VERSION ""

NS_ :

BS_:

BU_: EBCM ADAS PCM EPS VSA SCM BDY XXX EPB EON

BO_ 145 KINEMATICS: 8 XXX
 SG_ LAT_ACCEL : 7|8@0+ (0.02,-2.56) [-20|20] "m/s2" EON
 SG_ YAW : 39|8@0- (0.02,0) [0|255] "" XXX

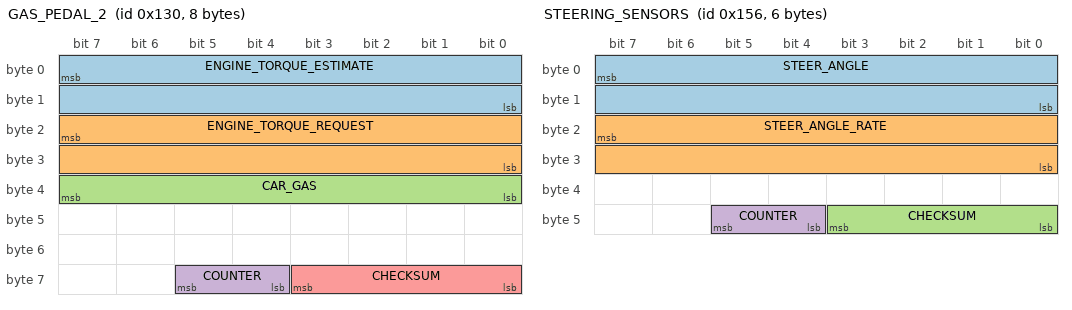
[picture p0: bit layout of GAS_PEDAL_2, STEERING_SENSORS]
BO_ 304 GAS_PEDAL_2: 8 PCM
 SG_ ENGINE_TORQUE_ESTIMATE : 7|16@0- (1,0) [-1000|1000] "Nm" EON
 SG_ ENGINE_TORQUE_REQUEST : 23|16@0- (1,0) [-1000|1000] "Nm" EON
 SG_ CAR_GAS : 39|8@0+ (1,0) [0|255] "" EON
 SG_ COUNTER : 61|2@0+ (1,0) [0|3] "" EON
 SG_ CHECKSUM : 59|4@0+ (1,0) [0|15] "" EON

BO_ 342 STEERING_SENSORS: 6 EPS
 SG_ STEER_ANGLE : 7|16@0- (-0.1,0) [-500|500] "deg" EON
 SG_ STEER_ANGLE_RATE : 23|16@0- (1,0) [-3000|3000] "deg/s" EON
 SG_ CHECKSUM : 43|4@0+ (1,0) [0|3] "" EON
 SG_ COUNTER : 45|2@0+ (1,0) [0|3] "" EON

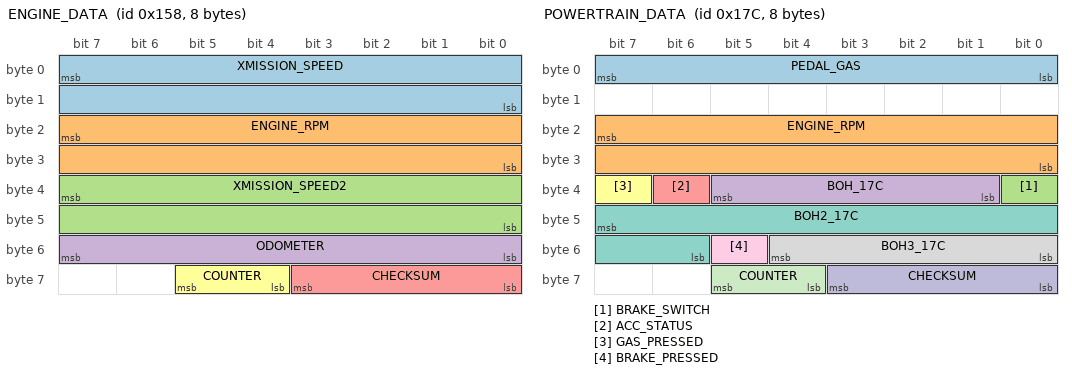
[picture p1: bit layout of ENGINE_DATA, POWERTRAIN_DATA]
BO_ 344 ENGINE_DATA: 8 PCM
 SG_ XMISSION_SPEED : 7|16@0+ (0.01,0) [0|250] "kph" EON
 SG_ ENGINE_RPM : 23|16@0+ (1,0) [0|15000] "rpm" EON
 SG_ XMISSION_SPEED2 : 39|16@0+ (0.01,0) [0|250] "kph" EON
 SG_ ODOMETER : 55|8@0+ (10,0) [0|2550] "m" XXX
 SG_ CHECKSUM : 59|4@0+ (1,0) [0|15] "" EON
 SG_ COUNTER : 61|2@0+ (1,0) [0|3] "" EON

BO_ 380 POWERTRAIN_DATA: 8 PCM
 SG_ PEDAL_GAS : 7|8@0+ (1,0) [0|255] "" EON
 SG_ ENGINE_RPM : 23|16@0+ (1,0) [0|15000] "rpm" EON
 SG_ BRAKE_SWITCH : 32|1@0+ (1,0) [0|1] "rpm" EON
 SG_ BOH_17C : 37|5@0+ (1,0) [0|1] "rpm" EON
 SG_ ACC_STATUS : 38|1@0+ (1,0) [0|1] "rpm" EON
 SG_ GAS_PRESSED : 39|1@0+ (1,0) [0|1] "" EON
 SG_ BOH2_17C : 47|10@0+ (1,0) [0|1] "rpm" EON
 SG_ BOH3_17C : 52|5@0+ (1,0) [0|1] "rpm" EON
 SG_ BRAKE_PRESSED : 53|1@0+ (1,0) [0|1] "" EON
 SG_ CHECKSUM : 59|4@0+ (1,0) [0|3] "" EON
 SG_ COUNTER : 61|2@0+ (1,0) [0|3] "" EON

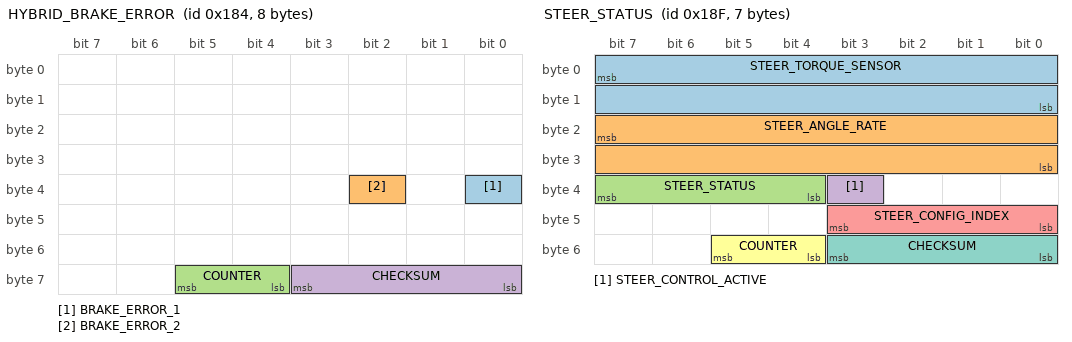
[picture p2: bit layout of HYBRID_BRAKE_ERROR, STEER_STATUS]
BO_ 388 HYBRID_BRAKE_ERROR: 8 XXX
 SG_ BRAKE_ERROR_1 : 32|1@0+ (1,0) [0|1] "" EON
 SG_ BRAKE_ERROR_2 : 34|1@0+ (1,0) [0|1] "" EON
 SG_ COUNTER : 61|2@0+ (1,0) [0|3] "" EON
 SG_ CHECKSUM : 59|4@0+ (1,0) [0|3] "" EON

BO_ 399 STEER_STATUS: 7 EPS
 SG_ STEER_TORQUE_SENSOR : 7|16@0- (-1,0) [-31000|31000] "tbd" EON
 SG_ STEER_ANGLE_RATE : 23|16@0- (-0.1,0) [-31000|31000] "deg/s" EON
 SG_ STEER_STATUS : 39|4@0+ (1,0) [0|15] "" EON
 SG_ STEER_CONTROL_ACTIVE : 35|1@0+ (1,0) [0|1] "" EON
 SG_ STEER_CONFIG_INDEX : 43|4@0+ (1,0) [0|15] "" EON
 SG_ COUNTER : 53|2@0+ (1,0) [0|3] "" EON
 SG_ CHECKSUM : 51|4@0+ (1,0) [0|3] "" EON

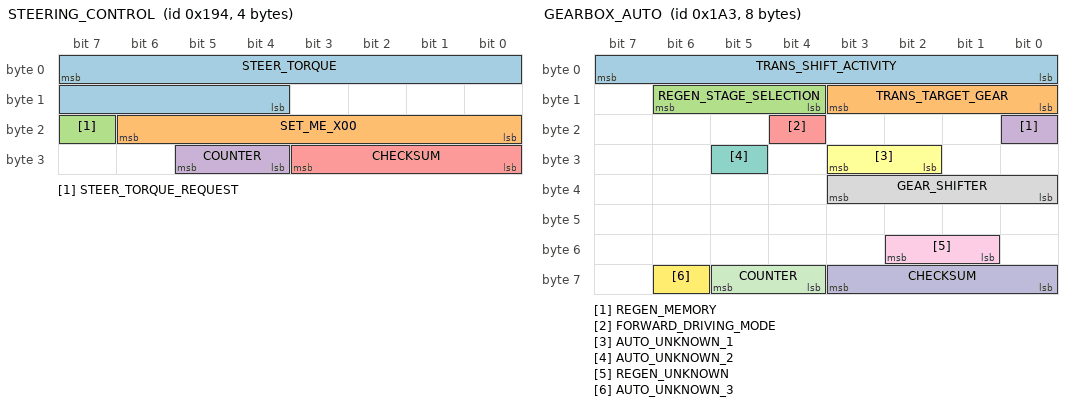
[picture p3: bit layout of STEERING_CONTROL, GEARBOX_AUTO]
BO_ 404 STEERING_CONTROL: 4 EON
 SG_ STEER_TORQUE : 7|12@0- (1,0) [-768|768] "" EPS
 SG_ SET_ME_X00 : 22|7@0+ (1,0) [0|127] "" EPS
 SG_ STEER_TORQUE_REQUEST : 23|1@0+ (1,0) [0|1] "" EPS
 SG_ COUNTER : 29|2@0+ (1,0) [0|15] "" EPS
 SG_ CHECKSUM : 27|4@0+ (1,0) [0|3] "" EPS

BO_ 419 GEARBOX_AUTO: 8 PCM
 SG_ TRANS_SHIFT_ACTIVITY : 7|8@0+ (1,0) [0|256] "" EON
 SG_ TRANS_TARGET_GEAR : 11|4@0+ (1,0) [0|15] "" XXX
 SG_ REGEN_STAGE_SELECTION : 14|3@0+ (1,0) [0|7] "Stage" XXX
 SG_ REGEN_MEMORY : 16|1@0+ (1,0) [0|1] "" XXX
 SG_ FORWARD_DRIVING_MODE : 20|1@0+ (1,0) [0|1] "" XXX
 SG_ AUTO_UNKNOWN_1 : 27|2@0+ (1,0) [0|3] "" XXX
 SG_ AUTO_UNKNOWN_2 : 29|1@0+ (1,0) [0|1] "" XXX
 SG_ GEAR_SHIFTER : 35|4@0+ (1,0) [0|15] "" EON
 SG_ REGEN_UNKNOWN : 50|2@0+ (1,0) [0|3] "" XXX
 SG_ CHECKSUM : 59|4@0+ (1,0) [0|3] "" EON
 SG_ COUNTER : 61|2@0+ (1,0) [0|3] "" EON
 SG_ AUTO_UNKNOWN_3 : 62|1@0+ (1,0) [0|1] "" XXX

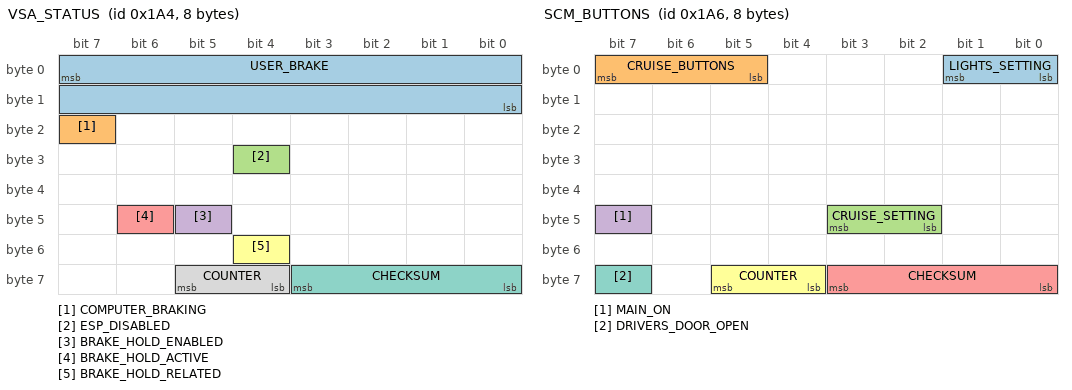
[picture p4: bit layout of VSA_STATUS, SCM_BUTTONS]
BO_ 420 VSA_STATUS: 8 VSA
 SG_ USER_BRAKE : 7|16@0+ (0.015625,-1.609375) [0|1000] "" EON
 SG_ COMPUTER_BRAKING : 23|1@0+ (1,0) [0|1] "" EON
 SG_ ESP_DISABLED : 28|1@0+ (1,0) [0|1] "" EON
 SG_ BRAKE_HOLD_ENABLED : 45|1@0+ (1,0) [0|1] "" EON
 SG_ BRAKE_HOLD_ACTIVE : 46|1@0+ (1,0) [0|1] "" EON
 SG_ BRAKE_HOLD_RELATED : 52|1@0+ (1,0) [0|1] "" XXX
 SG_ CHECKSUM : 59|4@0+ (1,0) [0|15] "" EON
 SG_ COUNTER : 61|2@0+ (1,0) [0|3] "" EON

BO_ 422 SCM_BUTTONS: 8 SCM
 SG_ LIGHTS_SETTING : 1|2@0+ (1,0) [0|3] "" EON
 SG_ CRUISE_BUTTONS : 7|3@0+ (1,0) [0|7] "" EON
 SG_ CRUISE_SETTING : 43|2@0+ (1,0) [0|3] "" EON
 SG_ MAIN_ON : 47|1@0+ (1,0) [0|1] "" EON
 SG_ CHECKSUM : 59|4@0+ (1,0) [0|3] "" EON
 SG_ COUNTER : 61|2@0+ (1,0) [0|3] "" EON
 SG_ DRIVERS_DOOR_OPEN : 63|1@0+ (1,0) [0|1] "" EON

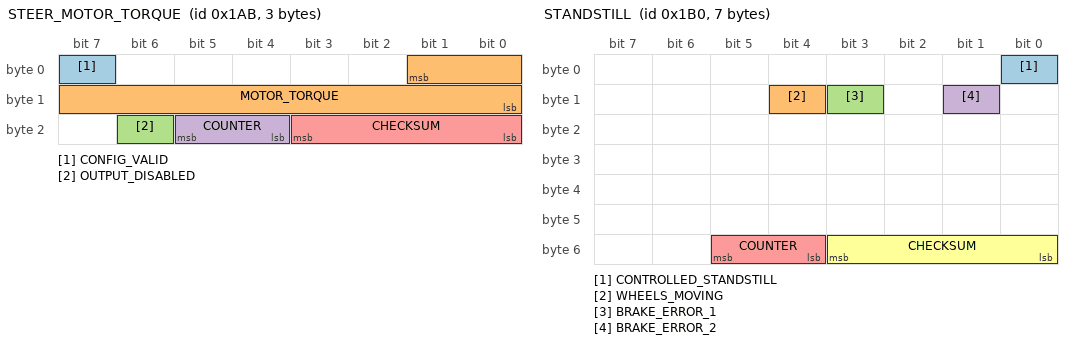
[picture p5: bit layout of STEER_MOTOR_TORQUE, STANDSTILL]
BO_ 427 STEER_MOTOR_TORQUE: 3 EPS
 SG_ CONFIG_VALID : 7|1@0+ (1,0) [0|1] "" EON
 SG_ MOTOR_TORQUE : 1|10@0+ (1,0) [0|256] "" EON
 SG_ OUTPUT_DISABLED : 22|1@0+ (1,0) [0|1] "" EON
 SG_ COUNTER : 21|2@0+ (1,0) [0|3] "" EON
 SG_ CHECKSUM : 19|4@0+ (1,0) [0|15] "" EON

BO_ 432 STANDSTILL: 7 VSA
 SG_ CONTROLLED_STANDSTILL : 0|1@0+ (1,0) [0|1] "" EON
 SG_ WHEELS_MOVING : 12|1@0+ (1,0) [0|1] "" EON
 SG_ BRAKE_ERROR_1 : 11|1@0+ (1,0) [0|1] "" EON
 SG_ BRAKE_ERROR_2 : 9|1@0+ (1,0) [0|1] "" EON
 SG_ COUNTER : 53|2@0+ (1,0) [0|3] "" EON
 SG_ CHECKSUM : 51|4@0+ (1,0) [0|3] "" EON

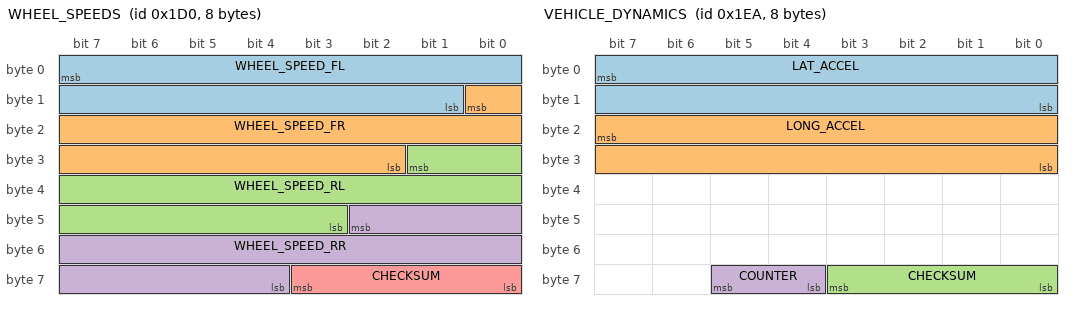
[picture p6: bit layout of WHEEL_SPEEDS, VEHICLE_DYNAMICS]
BO_ 464 WHEEL_SPEEDS: 8 VSA
 SG_ WHEEL_SPEED_FL : 7|15@0+ (0.01,0) [0|250] "kph" EON
 SG_ WHEEL_SPEED_FR : 8|15@0+ (0.01,0) [0|250] "kph" EON
 SG_ WHEEL_SPEED_RL : 25|15@0+ (0.01,0) [0|250] "kph" EON
 SG_ WHEEL_SPEED_RR : 42|15@0+ (0.01,0) [0|250] "kph" EON
 SG_ CHECKSUM : 59|4@0+ (1,0) [0|3] "" EON

BO_ 490 VEHICLE_DYNAMICS: 8 VSA
 SG_ LAT_ACCEL : 7|16@0- (0.0015,0) [-20|20] "m/s2" EON
 SG_ LONG_ACCEL : 23|16@0- (0.0015384,0) [-20|20] "m/s2" EON
 SG_ CHECKSUM : 59|4@0+ (1,0) [0|3] "" EON
 SG_ COUNTER : 61|2@0+ (1,0) [0|3] "" EON

BO_ 506 BRAKE_COMMAND: 8 ADAS
 SG_ COMPUTER_BRAKE : 7|10@0+ (1,0) [0|1] "" EBCM
 SG_ BRAKE_PUMP_REQUEST : 8|1@0+ (1,0) [0|1] "" EBCM
 SG_ BRAKE_PUMP_REQUEST_HYBRID : 11|1@0+ (1,0) [0|1] "" EBCM
 SG_ SET_ME_X00 : 23|3@0+ (1,0) [0|1] "" EBCM
 SG_ CRUISE_OVERRIDE : 20|1@0+ (1,0) [0|1] "" EBCM
 SG_ SET_ME_X00_2 : 19|1@0+ (1,0) [0|1] "" EBCM
 SG_ CRUISE_FAULT_CMD : 18|1@0+ (1,0) [0|1] "" EBCM
 SG_ CRUISE_CANCEL_CMD : 17|1@0+ (1,0) [0|1] "" EBCM
 SG_ COMPUTER_BRAKE_REQUEST : 16|1@0+ (1,0) [0|1] "" EBCM
 SG_ SET_ME_1 : 31|1@0+ (1,0) [0|1] "" EBCM
 SG_ AEB_REQ_1 : 29|1@0+ (1,0) [0|1] "" XXX
 SG_ AEB_REQ_2 : 26|3@0+ (1,0) [0|7] "" XXX
 SG_ BRAKE_LIGHTS : 39|1@0+ (1,0) [0|1] "" EBCM
 SG_ CRUISE_STATES : 38|7@0+ (1,0) [0|1] "" EBCM
 SG_ CHIME : 47|3@0+ (1,0) [0|7] "" EBCM
 SG_ SET_ME_X00_3 : 44|1@0+ (1,0) [0|1] "" EBCM
 SG_ FCW : 43|2@0+ (1,0) [0|3] "" EBCM
 SG_ AEB_STATUS : 41|2@0+ (1,0) [0|3] "" XXX
 SG_ COMPUTER_BRAKE_HYBRID : 55|10@0+ (1,0) [0|0] "" EBCM
 SG_ COUNTER : 61|2@0+ (1,0) [0|3] "" EBCM
 SG_ CHECKSUM : 59|4@0+ (1,0) [0|15] "" EBCM

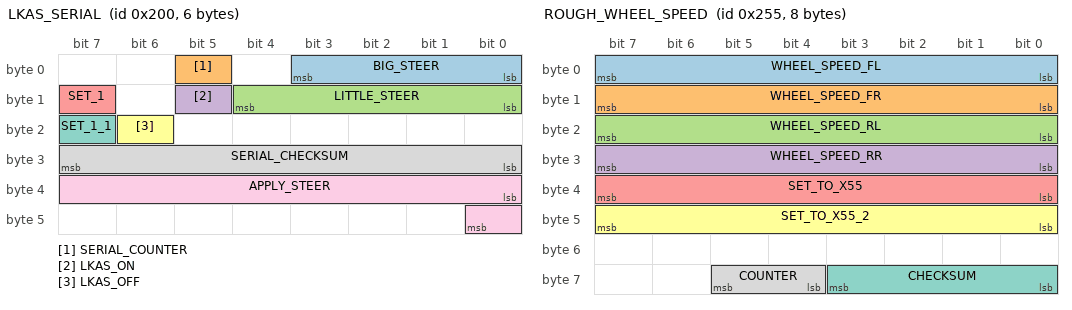
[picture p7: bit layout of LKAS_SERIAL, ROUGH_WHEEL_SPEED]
BO_ 512 LKAS_SERIAL: 6 XXX
 SG_ BIG_STEER : 3|4@0- (1,0) [0|15] "" XXX
 SG_ SERIAL_COUNTER : 5|1@0+ (1,0) [0|1] "" XXX
 SG_ LITTLE_STEER : 12|5@0- (1,0) [0|31] "" XXX
 SG_ LKAS_ON : 13|1@0+ (1,0) [0|1] "" XXX
 SG_ SET_1 : 15|1@0+ (1,0) [0|1] "" XXX
 SG_ LKAS_OFF : 22|1@0+ (1,0) [0|1] "" XXX
 SG_ SET_1_1 : 23|1@0+ (1,0) [0|1] "" XXX
 SG_ SERIAL_CHECKSUM : 24|8@1+ (1,32) [0|255] "" XXX
 SG_ APPLY_STEER : 32|9@1- (1,0) [-256|255] "" XXX

BO_ 521 LIN_DATA_IN: 8 XXX
 SG_ BIG_STEER : 0|4@1+ (1,0) [0|15] "" XXX
 SG_ UNK_SIGNAL : 4|1@0+ (1,0) [0|1] "" XXX
 SG_ LITTLE_STEER : 12|5@0+ (1,0) [0|31] "" XXX
 SG_ LKAS_ENABLED : 13|1@0+ (1,0) [0|1] "" XXX
 SG_ UNK_LDW_SIGNAL2 : 20|1@0+ (1,0) [0|1] "" XXX
 SG_ UNK_LDW_SIGNAL1 : 21|1@0+ (1,0) [0|1] "" XXX
 SG_ LKAS_ENABLED_INVERT : 22|1@0+ (1,0) [0|1] "" XXX
 SG_ BIG_DRIVER_TORQUE : 24|4@1+ (1,0) [0|15] "" XXX
 SG_ LIN_EPS_B0_O4 : 28|1@0+ (1,0) [0|1] "" XXX
 SG_ EPS_TO_LKAS_COUNTER_BIT : 29|1@0+ (1,0) [0|1] "" XXX
 SG_ SMALL_DRIVER_TORQUE : 36|5@0+ (1,0) [0|31] "" XXX
 SG_ LKAS_ON_FROM_EPS : 37|1@0+ (1,0) [0|1] "" XXX
 SG_ LIN_EPS_B1_O6 : 38|1@0+ (1,0) [0|1] "" XXX
 SG_ LIN_EPS_B2_O0_2 : 40|3@1+ (1,0) [0|7] "" XXX
 SG_ BIG_MOTOR_TORQUE : 45|3@0- (1,0) [0|7] "" XXX
 SG_ LKAS_ON_FROM_EPS_INVERT : 46|1@0+ (1,0) [0|1] "" XXX
 SG_ SMALL_MOTOR_TORQUE : 54|7@0+ (1,0) [0|127] "" XXX
 SG_ CAN_CHECKSUM : 56|4@1+ (1,0) [0|15] "" XXX
 SG_ CAN_COUNTER : 61|2@0+ (1,0) [0|3] "" XXX

BO_ 585 RLX_ENABLE: 8 XXX
 SG_ ENABLE : 3|12@0+ (1,-2048) [0|2048] "" XXX
 SG_ CHKSUM : 19|12@0+ (1,-2048) [0|2048] "" XXX

BO_ 597 ROUGH_WHEEL_SPEED: 8 VSA
 SG_ WHEEL_SPEED_FL : 7|8@0+ (1,0) [0|255] "mph" EON
 SG_ WHEEL_SPEED_FR : 15|8@0+ (1,0) [0|255] "mph" EON
 SG_ WHEEL_SPEED_RL : 23|8@0+ (1,0) [0|255] "mph" EON
 SG_ WHEEL_SPEED_RR : 31|8@0+ (1,0) [0|255] "mph" EON
 SG_ SET_TO_X55 : 39|8@0+ (1,0) [0|255] "" EON
 SG_ SET_TO_X55_2 : 47|8@0+ (1,0) [0|255] "" EON
 SG_ CHECKSUM : 59|4@0+ (1,0) [0|15] "" EON
 SG_ COUNTER : 61|2@0+ (1,0) [0|3] "" EON

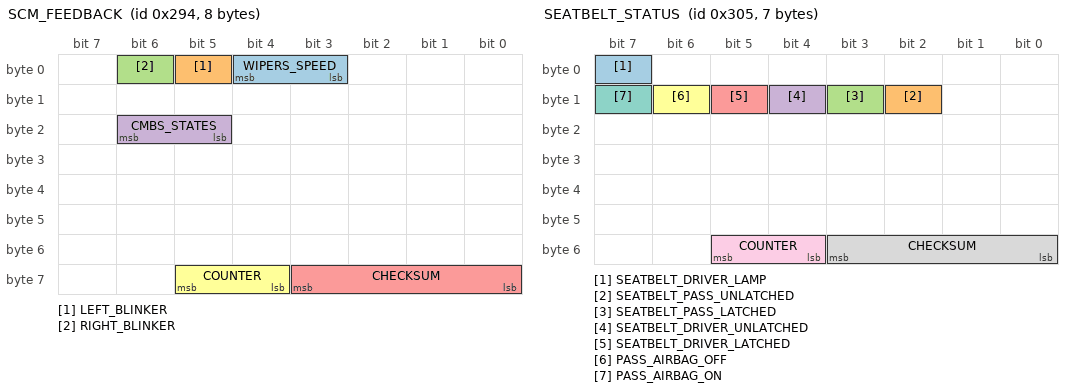
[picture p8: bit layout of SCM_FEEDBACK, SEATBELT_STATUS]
BO_ 660 SCM_FEEDBACK: 8 SCM
 SG_ WIPERS_SPEED : 4|2@0+ (1,0) [0|3] "" EON
 SG_ LEFT_BLINKER : 5|1@0+ (1,0) [0|1] "" EON
 SG_ RIGHT_BLINKER : 6|1@0+ (1,0) [0|1] "" EON
 SG_ CMBS_STATES : 22|2@0+ (1,0) [0|3] "" EON
 SG_ CHECKSUM : 59|4@0+ (1,0) [0|15] "" XXX
 SG_ COUNTER : 61|2@0+ (1,0) [0|3] "" XXX

BO_ 773 SEATBELT_STATUS: 7 BDY
 SG_ SEATBELT_DRIVER_LAMP : 7|1@0+ (1,0) [0|1] "" EON
 SG_ SEATBELT_PASS_UNLATCHED : 10|1@0+ (1,0) [0|1] "" EON
 SG_ SEATBELT_PASS_LATCHED : 11|1@0+ (1,0) [0|1] "" EON
 SG_ SEATBELT_DRIVER_UNLATCHED : 12|1@0+ (1,0) [0|1] "" EON
 SG_ SEATBELT_DRIVER_LATCHED : 13|1@0+ (1,0) [0|1] "" EON
 SG_ PASS_AIRBAG_OFF : 14|1@0+ (1,0) [0|1] "" EON
 SG_ PASS_AIRBAG_ON : 15|1@0+ (1,0) [0|1] "" EON
 SG_ CHECKSUM : 51|4@0+ (1,0) [0|3] "" EON
 SG_ COUNTER : 53|2@0+ (1,0) [0|3] "" EON

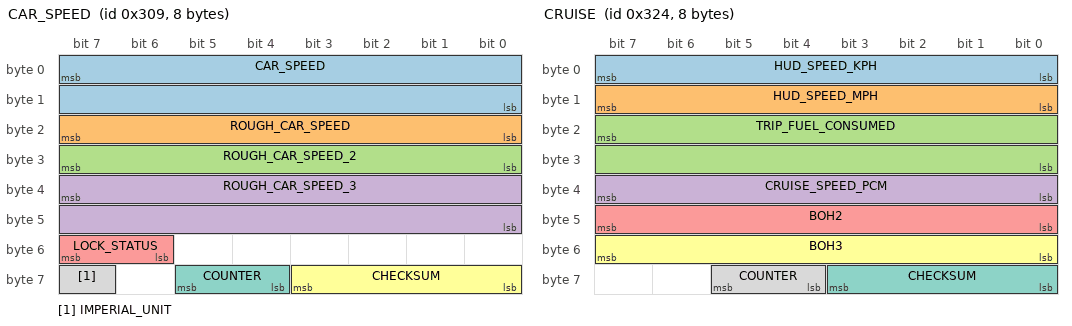
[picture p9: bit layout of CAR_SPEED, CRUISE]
BO_ 777 CAR_SPEED: 8 PCM
 SG_ CAR_SPEED : 7|16@0+ (0.01,0) [0|65535] "kph" XXX
 SG_ ROUGH_CAR_SPEED : 23|8@0+ (1,0) [0|255] "mph" XXX
 SG_ ROUGH_CAR_SPEED_2 : 31|8@0+ (1,0) [0|255] "mph" XXX
 SG_ ROUGH_CAR_SPEED_3 : 39|16@0+ (0.01,0) [0|65535] "mph" XXX
 SG_ LOCK_STATUS : 55|2@0+ (1,0) [0|255] "" XXX
 SG_ CHECKSUM : 59|4@0+ (1,0) [0|15] "" XXX
 SG_ COUNTER : 61|2@0+ (1,0) [0|3] "" XXX
 SG_ IMPERIAL_UNIT : 63|1@0+ (1,0) [0|1] "" XXX

BO_ 780 ACC_HUD: 8 XXX
 SG_ PCM_SPEED : 7|16@0+ (0.01,0) [0|250] "kph" BDY
 SG_ PCM_GAS : 23|8@0+ (1,0) [0|127] "" BDY
 SG_ CRUISE_SPEED : 31|8@0+ (1,0) [0|255] "kph" BDY
 SG_ ENABLE_MINI_CAR : 32|1@0+ (1,0) [0|1] "" BDY
 SG_ RADAR_OBSTRUCTED : 33|1@0+ (1,0) [0|1] "" BDY
 SG_ FCM_PROBLEM : 34|1@0+ (1,0) [0|1] "" BDY
 SG_ FCM_OFF : 35|1@0+ (1,0) [0|1] "" BDY
 SG_ FCM_OFF_2 : 36|1@0+ (1,0) [0|1] "" BDY
 SG_ ACC_PROBLEM : 37|1@0+ (1,0) [0|1] "" BDY
 SG_ BRAKE_SYSTEM_ICON : 38|1@0+ (1,0) [0|1] "" BDY
 SG_ DTC_MODE : 39|1@0+ (1,0) [0|1] "" BDY
 SG_ CRUISE_CONTROL_LABEL : 40|1@0+ (1,0) [0|3] "" BDY
 SG_ BOH_5 : 41|1@0+ (1,0) [0|3] "" BDY
 SG_ BOH_4 : 42|1@0+ (1,0) [0|3] "" BDY
 SG_ BOH_3 : 43|1@0+ (1,0) [0|3] "" BDY
 SG_ HUD_LEAD : 45|2@0+ (1,0) [0|3] "" BDY
 SG_ HUD_DISTANCE : 47|2@0+ (1,0) [0|3] "" BDY
 SG_ SET_ME_X01 : 48|1@0+ (1,0) [0|1] "" BDY
 SG_ CHIME : 51|3@0+ (1,0) [0|1] "" BDY
 SG_ ACC_ON : 52|1@0+ (1,0) [0|1] "" BDY
 SG_ IMPERIAL_UNIT : 54|1@0+ (1,0) [0|1] "" BDY
 SG_ SET_ME_X01_2 : 55|1@0+ (1,0) [0|1] "" BDY
 SG_ CHECKSUM : 59|4@0+ (1,0) [0|3] "" BDY
 SG_ COUNTER : 61|2@0+ (1,0) [0|3] "" BDY
 SG_ ICONS : 63|2@0+ (1,0) [0|1] "" BDY

BO_ 804 CRUISE: 8 PCM
 SG_ HUD_SPEED_KPH : 7|8@0+ (1,0) [0|255] "kph" EON
 SG_ HUD_SPEED_MPH : 15|8@0+ (1,0) [0|255] "mph" EON
 SG_ TRIP_FUEL_CONSUMED : 23|16@0+ (1,0) [0|255] "" EON
 SG_ CRUISE_SPEED_PCM : 39|8@0+ (1,0) [0|255] "" EON
 SG_ BOH2 : 47|8@0- (1,0) [0|255] "" EON
 SG_ BOH3 : 55|8@0+ (1,0) [0|255] "" EON
 SG_ CHECKSUM : 59|4@0+ (1,0) [0|3] "" EON
 SG_ COUNTER : 61|2@0+ (1,0) [0|3] "" EON

BO_ 829 LKAS_HUD: 5 ADAS
 SG_ SET_ME_X41 : 6|7@0+ (1,0) [0|127] "" BDY
 SG_ CAM_TEMP_HIGH : 7|1@0+ (1,0) [0|255] "" BDY
 SG_ STEERING_REQUIRED : 8|1@0+ (1,0) [0|1] "" BDY
 SG_ LDW_RIGHT : 9|1@0+ (1,0) [0|1] "" BDY
 SG_ SOLID_LANES : 10|1@0+ (1,0) [0|1] "" BDY
 SG_ LKAS_OFF : 11|1@0+ (1,0) [0|1] "" BDY
 SG_ LKAS_PROBLEM : 12|1@0+ (1,0) [0|1] "" BDY
 SG_ DTC : 13|1@0+ (1,0) [0|1] "" BDY
 SG_ DASHED_LANES : 14|1@0+ (1,0) [0|1] "" BDY
 SG_ BEEP : 17|2@0+ (1,0) [0|1] "" BDY
 SG_ LDW_PROBLEM : 21|1@0+ (1,0) [0|1] "" BDY
 SG_ BOH : 23|2@0+ (1,0) [0|4] "" BDY
 SG_ CLEAN_WINDSHIELD : 26|1@0+ (1,0) [0|1] "" BDY
 SG_ LDW_OFF : 27|1@0+ (1,0) [0|1] "" BDY
 SG_ LDW_ON : 28|1@0+ (1,0) [0|1] "" BDY
 SG_ SET_ME_X48 : 31|8@0+ (1,0) [0|255] "" BDY
 SG_ CHECKSUM : 35|4@0+ (1,0) [0|15] "" BDY
 SG_ COUNTER : 37|2@0+ (1,0) [0|3] "" BDY

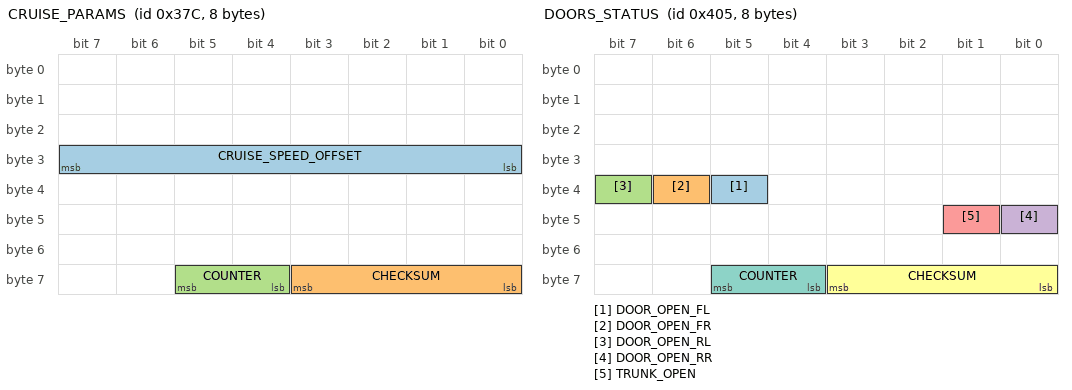
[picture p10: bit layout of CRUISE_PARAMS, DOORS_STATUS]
BO_ 892 CRUISE_PARAMS: 8 PCM
 SG_ CRUISE_SPEED_OFFSET : 31|8@0- (0.1,0) [-128|127] "kph" EON
 SG_ CHECKSUM : 59|4@0+ (1,0) [0|3] "" EON
 SG_ COUNTER : 61|2@0+ (1,0) [0|3] "" EON

BO_ 1029 DOORS_STATUS: 8 BDY
 SG_ DOOR_OPEN_FL : 37|1@0+ (1,0) [0|1] "" EON
 SG_ DOOR_OPEN_FR : 38|1@0+ (1,0) [0|1] "" EON
 SG_ DOOR_OPEN_RL : 39|1@0+ (1,0) [0|1] "" EON
 SG_ DOOR_OPEN_RR : 40|1@0+ (1,0) [0|1] "" EON
 SG_ TRUNK_OPEN : 41|1@0+ (1,0) [0|1] "" EON
 SG_ CHECKSUM : 59|4@0+ (1,0) [0|3] "" EON
 SG_ COUNTER : 61|2@0+ (1,0) [0|3] "" EON

CM_ SG_ 228 SEND_LIN_WHOLE_DATA "takes the MCU LKAS STEER_TORQUE, EPS";
CM_ SG_ 228 LDW_SIGNAL_2 "LKAS B1O4";
CM_ SG_ 228 LDW_SIGNAL_1 "LKAS B1 5";
CM_ SG_ 427 EPS_LKAS_ON "Signal from EPStoLKAS B1 O5";
CM_ SG_ 490 LONG_ACCEL "wheel speed derivative, noisy and zero snapping";
CM_ SG_ 506 AEB_REQ_1 "set for duration of suspected AEB event";
CM_ SG_ 512 APPLY_STEER "thi sis big_steer and little_steer put together";
CM_ SG_ 521 UNK_SIGNAL "ive never seen this move like this..";
CM_ SG_ 773 PASS_AIRBAG_OFF "Might just be indicator light";
CM_ SG_ 773 PASS_AIRBAG_ON "Might just be indicator light";
CM_ SG_ 780 CRUISE_SPEED "255 = no speed";
CM_ SG_ 804 CRUISE_SPEED_PCM "255 = no speed";
CM_ SG_ 829 BEEP "beeps are pleasant, chimes are for warnngs etc...";
VAL_ 399 STEER_STATUS 7 "permanent_fault" 6 "tmp_fault" 5 "fault_1" 4 "no_torque_alert_2" 3 "low_speed_lockout" 2 "no_torque_alert_1" 1 "driver_steering" 0 "normal" ;
VAL_ 419 GEAR_SHIFTER 1 "P" 2 "R" 3 "N" 4 "D" 7 "L" 10 "S";
VAL_ 419 TRANS_TARGET_GEAR 0 "None / Neutral / Park" 1 "1st" 2 "2nd" 3 "3rd" 4 "4th" 5 "5th" 6 "6th" 7 "7th" 8 "8th" 9 "9th" 10 "10th" 13 "Reverse";
VAL_ 419 REGEN_STAGE_SELECTION 0 "disabled" 1 "stage_1" 2 "stage_2" 3 "stage_3" 4 "stage_4" 5 "stage_5" 6 "stage_6";
VAL_ 419 REGEN_MEMORY 0 "disabled" 1 "persistent";
VAL_ 422 LIGHTS_SETTING 3 "high_beam" 2 "low_beam" 1 "position" 0 "no_lights";
VAL_ 422 CRUISE_BUTTONS 7 "tbd" 6 "tbd" 5 "tbd" 4 "accel_res" 3 "decel_set" 2 "cancel" 1 "main" 0 "none";
VAL_ 422 CRUISE_SETTING 3 "distance_adj" 2 "tbd" 1 "lkas_button" 0 "none";
VAL_ 506 AEB_STATUS 3 "aeb_prepare" 2 "aeb_ready" 1 "aeb_braking" 0 "no_aeb";
VAL_ 506 FCW 3 "fcw" 2 "fcw" 1 "fcw" 0 "no_fcw";
VAL_ 506 CHIME 4 "double_chime" 3 "single_chime" 2 "continuous_chime" 1 "repeating_chime" 0 "no_chime";
VAL_ 780 CRUISE_SPEED 255 "no_speed" 252 "stopped";
VAL_ 780 HUD_LEAD 3 "acc_off" 2 "solid_car" 1 "dashed_car" 0 "no_car";
VAL_ 829 BEEP 3 "single_beep" 2 "triple_beep" 1 "repeated_beep" 0 "no_beep";
